# DMASS_DTHE_DMASS_DTHE_DTHE_DTHE_CFG_DTHE_REGS_WRAP_VBUSP_CRC_P_40802000h register map
Vendor: Texas Instruments
Peripheral module from a debugger description file (folder am62L).
Registers are 32-bit, read-write, reset 0x0 unless marked. A register's access mark holds for its fields unless they carry their own. Offsets are as the file gives them; lines under a group give offsets from that group; [hi:lo] are bit positions; {n}, {i} and the like mark numbered series; 'fields as' and 'values as' point back to an identical list; <NAME> marks a mode.

## DMASS_DTHE_DTHE_DTHE_CFG_DTHE_REGS_WRAP_VBUSP_CRC_P
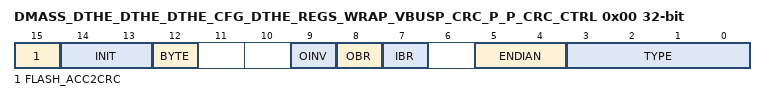
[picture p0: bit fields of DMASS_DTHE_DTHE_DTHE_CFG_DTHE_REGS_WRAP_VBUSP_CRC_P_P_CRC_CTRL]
0x00 DMASS_DTHE_DTHE_DTHE_CFG_DTHE_REGS_WRAP_VBUSP_CRC_P_P_CRC_CTRL — Context_1 CRC Control register
  [15] FLASH_ACC2CRC — This bit is deprecated and has no functional use
  [14:13] INIT — Initialize the CRC 00:use SEED register context as starting value 10:all zero 11:all one. This is self clearing. With first write to data register this value clears to zero and remain zero for rest of the operation unless written again
  [12] BYTE — Input data size 0:32bit 1:8bit
  [9] OINV — Inverse the bits of result before storing to CRC_RSLT_PP0
  [8] OBR — Bit reserved the output result byte before storing to CRC_RSLT_PP0. applicable for all bytes in word
  [7] IBR — Bit reverse the input byte. For all bytes in word
  [5:4] ENDIAN — Endian control [0]swap byte in half-word [1]swap half word
  [3:0] TYPE — Type of operation 0000 polynomial 0x8005 0001 polynomial 0x1021 0010 polynomial 0x4C11DB7 0011 polynomial 0x1EDC6F41 1000 TCP checksum TYPE in DTHE_S_CRC_CTRL & DTHE_S_CRC_CTRL should be exclusive
0x20 DMASS_DTHE_DTHE_DTHE_CFG_DTHE_REGS_WRAP_VBUSP_CRC_P_P_CRC_SEED — Context_1 CRC Seed register
  [31:0] SEED — Starting seed of CRC and checksum operation. Please see CTRL register for more detail. This resister also holds the latest result of CRC or checksum operation
0x40 DMASS_DTHE_DTHE_DTHE_CFG_DTHE_REGS_WRAP_VBUSP_CRC_P_P_CRC_DIN — Context_1 CRC Data Input register
  [31:0] DATA_IN — Input data for CRC or checksum operation
0x60 DMASS_DTHE_DTHE_DTHE_CFG_DTHE_REGS_WRAP_VBUSP_CRC_P_P_CRC_RSLT_PP ro — Context_1 CRC Result After post-processing register
  [31:0] RSLT_PP — result data of CRC or checksum operation
